# ATmega1284P register map
Vendor: Atmel; Series: ATmega128; File version: 1.1
CPU: other r0p0, little endian, no MPU, no FPU, VTOR, 4 interrupt priority bits
Registers are 8-bit, read-write, reset 0x0 unless marked. A register's access mark holds for its fields unless they carry their own. Offsets are from the block's base; [hi:lo] are bit positions; 'fields as' and 'values as' point back to an identical list.

## TC2 — Timer/Counter, 8-bit Async
Base 0x00000037
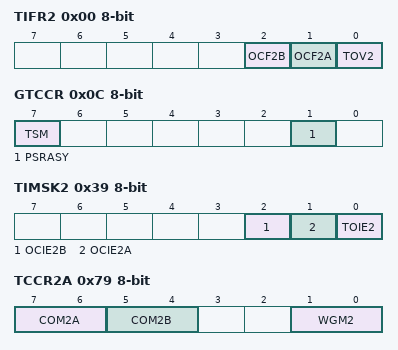
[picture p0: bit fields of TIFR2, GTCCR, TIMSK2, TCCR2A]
0x00 TIFR2 — Timer/Counter Interrupt Flag Register
  [2] OCF2B — Output Compare Flag 2B
  [1] OCF2A — Output Compare Flag 2A
  [0] TOV2 — Timer/Counter2 Overflow Flag
0x0C GTCCR — General Timer Counter Control register
  [7] TSM — Timer/Counter Synchronization Mode
  [1] PSRASY — Prescaler Reset Timer/Counter2
0x39 TIMSK2 — Timer/Counter Interrupt Mask register
  [2] OCIE2B — Timer/Counter2 Output Compare Match B Interrupt Enable
  [1] OCIE2A — Timer/Counter2 Output Compare Match A Interrupt Enable
  [0] TOIE2 — Timer/Counter2 Overflow Interrupt Enable
0x79 TCCR2A — Timer/Counter2 Control Register A
  [7:6] COM2A — Compare Output A Mode bits
    0=DISCONNECTED (Normal port operation, OCix disconnected); 1=MATCH_TOGGLE (Toggle OCix on Compare Match (Might depend on WGM)); 2=MATCH_CLEAR (Clear OCix on Compare Match (If PWM is enabled, OCix is set at TOP)); 3=MATCH_SET (Set OCix on Compare Match (If PWM is enabled, OCix is cleared at TOP))
  [5:4] COM2B — Compare Output B Mode bits
    values as COM2A
  [1:0] WGM2 — Waveform Genration Mode
    0=NORMAL_TOP (Normal, Top: `0xff`, Update: *Immediate*, Flag: *MAX*); 1=PWM_PHASE (Phase Correct PWM, Top: `0xff`, Update: *TOP*, Flag: *BOTTOM*); 2=CTC (CTC, Top: *OCRA*, Update: *Immediate*, Flag: *MAX*); 3=PWM_FAST (Fast PWM, Top: `0xff`, Update: *TOP*, Flag: *MAX*)
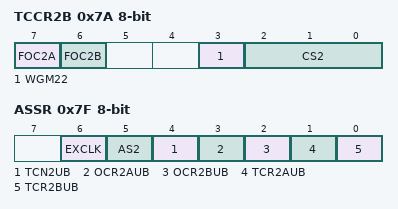
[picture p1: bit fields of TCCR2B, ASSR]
0x7A TCCR2B — Timer/Counter2 Control Register B
  [7] FOC2A wo — Force Output Compare A
  [6] FOC2B wo — Force Output Compare B
  [3] WGM22 — Waveform Generation Mode High Bit (Enable Top: *OCRA* for `PWM` modes)
  [2:0] CS2 — Clock Select bits
    0=NO_CLOCK (No clock source (Timer/Counter stopped)); 1=DIRECT (Running, No Prescaling); 2=PRESCALE_8 (Running, CLK/8); 3=PRESCALE_32 (Running, CLK/32); 4=PRESCALE_64 (Running, CLK/64); 5=PRESCALE_128 (Running, CLK/128); 6=PRESCALE_256 (Running, CLK/256); 7=PRESCALE_1024 (Running, CLK/1024)
0x7B TCNT2 — Timer/Counter2
  [7:0] TCNT2 — Timer/Counter2 bits
0x7C OCR2A — Timer/Counter2 Output Compare Register A
  [7:0] OCR2A — Timer/Counter2 Output Compare A bits
0x7D OCR2B — Timer/Counter2 Output Compare Register B
  [7:0] OCR2B — Timer/Counter2 Output Compare B bits
0x7F ASSR — Asynchronous Status Register
  [6] EXCLK — Enable External Clock Input
  [5] AS2 — Asynchronous Timer/Counter2
  [4] TCN2UB — Timer/Counter2 Update Busy
  [3] OCR2AUB — Output Compare Register2 Update Busy
  [2] OCR2BUB — Output Compare Register 2 Update Busy
  [1] TCR2AUB — Timer/Counter Control Register2 Update Busy
  [0] TCR2BUB — Timer/Counter Control Register2 Update Busy

## TC3 — Timer/Counter, 16-bit
Base 0x00000038
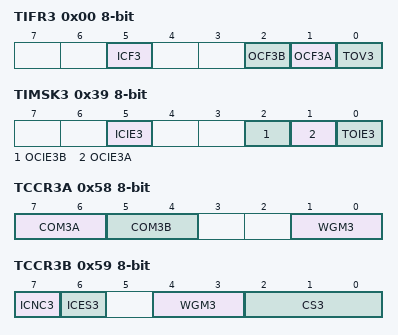
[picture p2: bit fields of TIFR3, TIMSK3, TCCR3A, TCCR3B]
0x00 TIFR3 — Timer/Counter Interrupt Flag register
  [5] ICF3 — Timer/Counter3 Input Capture Flag
  [2] OCF3B — Timer/Counter3 Output Compare B Match Flag
  [1] OCF3A — Timer/Counter3 Output Compare A Match Flag
  [0] TOV3 — Timer/Counter3 Overflow Flag
0x39 TIMSK3 — Timer/Counter3 Interrupt Mask Register
  [5] ICIE3 — Timer/Counter3 Input Capture Interrupt Enable
  [2] OCIE3B — Timer/Counter3 Output Compare B Match Interrupt Enable
  [1] OCIE3A — Timer/Counter3 Output Compare A Match Interrupt Enable
  [0] TOIE3 — Timer/Counter3 Overflow Interrupt Enable
0x58 TCCR3A — Timer/Counter3 Control Register A
  [7:6] COM3A — Compare Output Mode 3A, bits
    0=DISCONNECTED (Normal port operation, OCix disconnected); 1=MATCH_TOGGLE (Toggle OCix on Compare Match (Might depend on WGM)); 2=MATCH_CLEAR (Clear OCix on Compare Match (If PWM is enabled, OCix is set at BOTTOM)); 3=MATCH_SET (Set OCix on Compare Match (If PWM is enabled, OCix is cleared at BOTTOM))
  [5:4] COM3B — Compare Output Mode 3B, bits
    values as COM3A
  [1:0] WGM3 — Pulse Width Modulator Select Bits
0x59 TCCR3B — Timer/Counter3 Control Register B
  [7] ICNC3 — Input Capture 3 Noise Canceler
  [6] ICES3 — Input Capture 3 Edge Select
  [4:3] WGM3 — Waveform Generation Mode Bits
  [2:0] CS3 — Clock Select3 bits
    0=NO_CLOCK (No clock source (Timer/Counter stopped)); 1=DIRECT (Running, No Prescaling); 2=PRESCALE_8 (Running, CLK/8); 3=PRESCALE_64 (Running, CLK/64); 4=PRESCALE_256 (Running, CLK/256); 5=PRESCALE_1024 (Running, CLK/1024); 6=EXT_FALLING (Running, ExtClk Tx Falling Edge); 7=EXT_RISING (Running, ExtClk Tx Rising Edge)
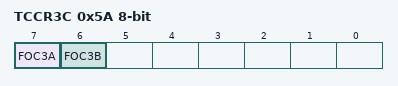
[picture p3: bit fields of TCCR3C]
0x5A TCCR3C — Timer/Counter3 Control Register C
  [7] FOC3A wo — Force Output Compare for Channel A
  [6] FOC3B wo — Force Output Compare for Channel B
0x5C TCNT3 16-bit (reset mask 0xFF) — Timer/Counter3 Bytes
  [15:0] TCNT3 — Timer/Counter3 bits
0x5E ICR3 16-bit (reset mask 0xFF) — Timer/Counter3 Input Capture Register Bytes
  [15:0] ICR3 — Timer/Counter3 Input Capture bits
0x60 OCR3A 16-bit (reset mask 0xFF) — Timer/Counter3 Output Compare Register A Bytes
  [15:0] OCR3A — Timer/Counter3 Output Compare A bits
0x62 OCR3B 16-bit (reset mask 0xFF) — Timer/Counter3 Output Compare Register B Bytes
  [15:0] OCR3B — Timer/Counter3 Output Compare B bits
